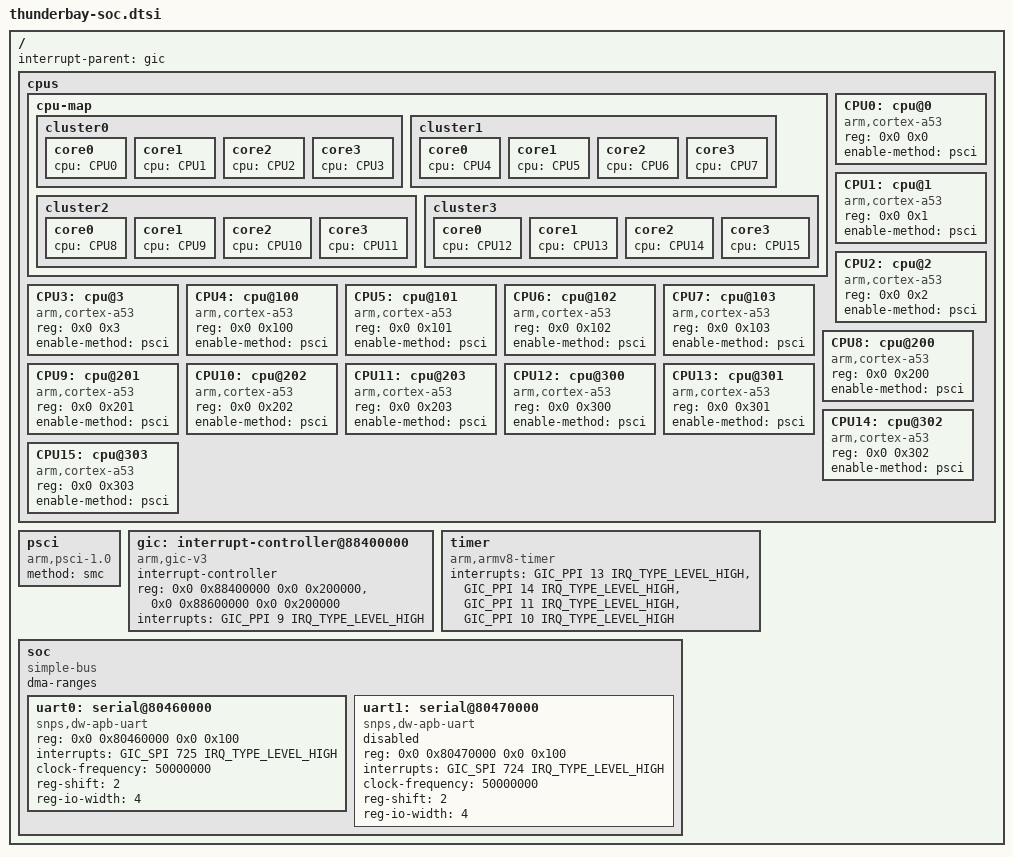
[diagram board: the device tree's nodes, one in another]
// SPDX-License-Identifier: (GPL-2.0-only OR BSD-3-Clause)
/*
 * Copyright (c) 2021 Intel Corporation.
 *
 * Device tree describing Thunder Bay SoC
 */

#include <dt-bindings/interrupt-controller/arm-gic.h>

/ {

	#address-cells = <2>;
	#size-cells = <2>;
	interrupt-parent = <&gic>;

	cpus {
		#address-cells = <2>;
		#size-cells = <0>;

		cpu-map {
			cluster0 {
				core0 {
					cpu = <&CPU0>;
				};
				core1 {
					cpu = <&CPU1>;
				};
				core2 {
					cpu = <&CPU2>;
				};
				core3 {
					cpu = <&CPU3>;
				};
			};
			cluster1 {
				core0 {
					cpu = <&CPU4>;
				};
				core1 {
					cpu = <&CPU5>;
				};
				core2 {
					cpu = <&CPU6>;
				};
				core3 {
					cpu = <&CPU7>;
				};
			};
			cluster2 {
				core0 {
					cpu = <&CPU8>;
				};
				core1 {
					cpu = <&CPU9>;
				};
				core2 {
					cpu = <&CPU10>;
				};
				core3 {
					cpu = <&CPU11>;
				};
			};
			cluster3 {
				core0 {
					cpu = <&CPU12>;
				};
				core1 {
					cpu = <&CPU13>;
				};
				core2 {
					cpu = <&CPU14>;
				};
				core3 {
					cpu = <&CPU15>;
				};
			};
		};

		CPU0: cpu@0 {
			compatible = "arm,cortex-a53";
			device_type = "cpu";
			reg = <0x0 0x0>;
			enable-method = "psci";
		};

		CPU1: cpu@1 {
			compatible = "arm,cortex-a53";
			device_type = "cpu";
			reg = <0x0 0x1>;
			enable-method = "psci";
		};

		CPU2: cpu@2 {
			compatible = "arm,cortex-a53";
			device_type = "cpu";
			reg = <0x0 0x2>;
			enable-method = "psci";
		};

		CPU3: cpu@3 {
			compatible = "arm,cortex-a53";
			device_type = "cpu";
			reg = <0x0 0x3>;
			enable-method = "psci";
		};

		CPU4: cpu@100 {
			compatible = "arm,cortex-a53";
			device_type = "cpu";
			reg = <0x0 0x100>;
			enable-method = "psci";
		};

		CPU5: cpu@101 {
			compatible = "arm,cortex-a53";
			device_type = "cpu";
			reg = <0x0 0x101>;
			enable-method = "psci";
		};

		CPU6: cpu@102 {
			compatible = "arm,cortex-a53";
			device_type = "cpu";
			reg = <0x0 0x102>;
			enable-method = "psci";
		};

		CPU7: cpu@103 {
			compatible = "arm,cortex-a53";
			device_type = "cpu";
			reg = <0x0 0x103>;
			enable-method = "psci";
		};

		CPU8: cpu@200 {
			compatible = "arm,cortex-a53";
			device_type = "cpu";
			reg = <0x0 0x200>;
			enable-method = "psci";
		};

		CPU9: cpu@201 {
			compatible = "arm,cortex-a53";
			device_type = "cpu";
			reg = <0x0 0x201>;
			enable-method = "psci";
		};

		CPU10: cpu@202 {
			compatible = "arm,cortex-a53";
			device_type = "cpu";
			reg = <0x0 0x202>;
			enable-method = "psci";
		};

		CPU11: cpu@203 {
			compatible = "arm,cortex-a53";
			device_type = "cpu";
			reg = <0x0 0x203>;
			enable-method = "psci";
		};

		CPU12: cpu@300 {
			compatible = "arm,cortex-a53";
			device_type = "cpu";
			reg = <0x0 0x300>;
			enable-method = "psci";
		};

		CPU13: cpu@301 {
			compatible = "arm,cortex-a53";
			device_type = "cpu";
			reg = <0x0 0x301>;
			enable-method = "psci";
		};

		CPU14: cpu@302 {
			compatible = "arm,cortex-a53";
			device_type = "cpu";
			reg = <0x0 0x302>;
			enable-method = "psci";
		};

		CPU15: cpu@303 {
			compatible = "arm,cortex-a53";
			device_type = "cpu";
			reg = <0x0 0x303>;
			enable-method = "psci";
		};
	};

	psci {
		compatible = "arm,psci-1.0";
		method = "smc";
	};

	gic: interrupt-controller@88400000 {
		compatible = "arm,gic-v3";
		interrupt-controller;
		#interrupt-cells = <3>;
		reg = <0x0 0x88400000 0x0 0x200000>,	/* GICD */
		      <0x0 0x88600000 0x0 0x200000>;	/* GICR */
		/* VGIC maintenance interrupt */
		interrupts = <GIC_PPI 9 IRQ_TYPE_LEVEL_HIGH>;
	};

	timer {
		compatible = "arm,armv8-timer";
		/* Secure, non-secure, virtual, and hypervisor */
		interrupts = <GIC_PPI 13 IRQ_TYPE_LEVEL_HIGH>,
			     <GIC_PPI 14 IRQ_TYPE_LEVEL_HIGH>,
			     <GIC_PPI 11 IRQ_TYPE_LEVEL_HIGH>,
			     <GIC_PPI 10 IRQ_TYPE_LEVEL_HIGH>;
	};

	soc {
		compatible = "simple-bus";
		#address-cells = <2>;
		#size-cells = <2>;
		ranges;
		dma-ranges;

		uart0: serial@80460000 {
			compatible = "snps,dw-apb-uart";
			reg = <0x0 0x80460000 0x0 0x100>;
			interrupts = <GIC_SPI 725 IRQ_TYPE_LEVEL_HIGH>;
			clock-frequency = <50000000>;
			reg-shift = <2>;
			reg-io-width = <4>;
		};

		uart1: serial@80470000 {
			compatible = "snps,dw-apb-uart";
			reg = <0x0 0x80470000 0x0 0x100>;
			interrupts = <GIC_SPI 724 IRQ_TYPE_LEVEL_HIGH>;
			clock-frequency = <50000000>;
			reg-shift = <2>;
			reg-io-width = <4>;
			status = "disabled";
		};
	};
};
